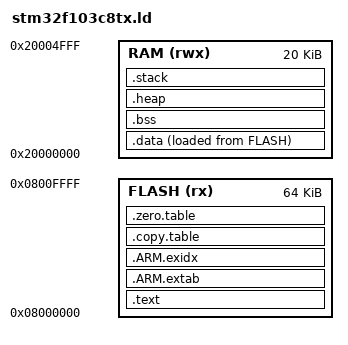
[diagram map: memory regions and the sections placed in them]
__ROM_BASE = 0x08000000;
__ROM_SIZE = 0x00010000;
__RAM_BASE = 0x20000000;
__RAM_SIZE = 0x00005000;

__STACK_SIZE = 0x00000400;
__HEAP_SIZE  = 0x00000C00;
__STACKSEAL_SIZE = 0;

MEMORY
{
  FLASH (rx)  : ORIGIN = 0x08000000, LENGTH = 64K
  RAM   (rwx) : ORIGIN = 0x20000000, LENGTH = 20K
}

ENTRY(Reset_Handler)

SECTIONS
{
  .text :
  {
    KEEP(*(.vectors))
    *(.text*)
    KEEP(*(.init))
    KEEP(*(.fini))
    *crtbegin.o(.ctors)
    *crtbegin?.o(.ctors)
    *(EXCLUDE_FILE(*crtend?.o *crtend.o) .ctors)
    *(SORT(.ctors.*))
    *(.ctors)
    *crtbegin.o(.dtors)
    *crtbegin?.o(.dtors)
    *(EXCLUDE_FILE(*crtend?.o *crtend.o) .dtors)
    *(SORT(.dtors.*))
    *(.dtors)
    *(.rodata*)
    KEEP(*(.eh_frame*))
  } > FLASH

  .ARM.extab :
  {
    *(.ARM.extab* .gnu.linkonce.armextab.*)
  } > FLASH

  __exidx_start = .;
  .ARM.exidx :
  {
    *(.ARM.exidx* .gnu.linkonce.armexidx.*)
  } > FLASH
  __exidx_end = .;

  .copy.table :
  {
    . = ALIGN(4);
    __copy_table_start__ = .;
    LONG (LOADADDR(.data))
    LONG (ADDR(.data))
    LONG (SIZEOF(.data) / 4)
    __copy_table_end__ = .;
  } > FLASH

  .zero.table :
  {
    . = ALIGN(4);
    __zero_table_start__ = .;
    __zero_table_end__ = .;
  } > FLASH

  PROVIDE(__etext = LOADADDR(.data));

  .data : ALIGN(4)
  {
    __data_start__ = .;
    *(vtable)
    *(.data)
    *(.data.*)
    . = ALIGN(4);
    PROVIDE_HIDDEN (__preinit_array_start = .);
    KEEP(*(.preinit_array))
    PROVIDE_HIDDEN (__preinit_array_end = .);
    . = ALIGN(4);
    PROVIDE_HIDDEN (__init_array_start = .);
    KEEP(*(SORT(.init_array.*)))
    KEEP(*(.init_array))
    PROVIDE_HIDDEN (__init_array_end = .);
    . = ALIGN(4);
    PROVIDE_HIDDEN (__fini_array_start = .);
    KEEP(*(SORT(.fini_array.*)))
    KEEP(*(.fini_array))
    PROVIDE_HIDDEN (__fini_array_end = .);
    KEEP(*(.jcr*))
    . = ALIGN(4);
    __data_end__ = .;
  } > RAM AT > FLASH

  .bss :
  {
    . = ALIGN(4);
    __bss_start__ = .;
    *(.bss)
    *(.bss.*)
    *(COMMON)
    . = ALIGN(4);
    __bss_end__ = .;
  } > RAM AT > RAM

  .heap (NOLOAD) :
  {
    . = ALIGN(8);
    __end__ = .;
    PROVIDE(end = .);
    . = . + __HEAP_SIZE;
    . = ALIGN(8);
    __HeapLimit = .;
  } > RAM

  .stack (ORIGIN(RAM) + LENGTH(RAM) - __STACK_SIZE - __STACKSEAL_SIZE) (NOLOAD) :
  {
    . = ALIGN(8);
    __StackLimit = .;
    . = . + __STACK_SIZE;
    . = ALIGN(8);
    __StackTop = .;
  } > RAM
  PROVIDE(__stack = __StackTop);

  ASSERT(__StackLimit >= __HeapLimit, "region RAM overflowed with stack")
}
